AUTOSAR XML (schema 00050)
package /FCADT/ComponentTypes
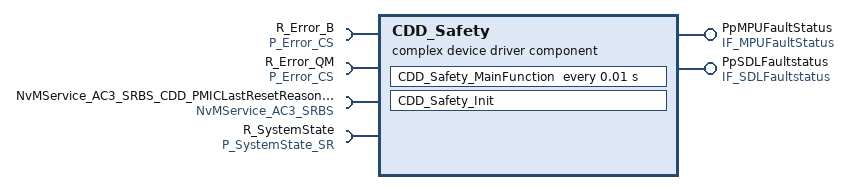
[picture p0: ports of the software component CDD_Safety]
  complex device driver sw component type CDD_Safety
    require port R_Error_B: client-com-spec=ReportErrorStatus1_0_B, required-interface=P_Error_CS
    require port R_Error_QM: client-com-spec=ReportErrorStatus1_0_QM, required-interface=P_Error_CS
    provide port PpMPUFaultStatus: nonqueued-sender-com-spec{data-element=Sts, init-value=[0, 0]}, provided-interface=IF_MPUFaultStatus
    provide port PpSDLFaultstatus: nonqueued-sender-com-spec{data-element=Sts, init-value=14 x 0}, provided-interface=IF_SDLFaultstatus
    require port NvMService_AC3_SRBS_CDD_PMICLastResetReason_BISTStatus: required-com-specs=[WriteBlock, SetRamBlockStatus, ReadBlock, InvalidateNvBlock, GetErrorStatus, EraseBlock], required-interface=NvMService_AC3_SRBS
    require port R_SystemState: nonqueued-receiver-com-spec=data-element=SystemState, required-interface=P_SystemState_SR
    behavior CDD_Safety_InternalBehavior
      ar-typed-per-instance-memorys:
        data CDD_PMICLastResetReason_BISTStatus_MirrorBlock: sw-calibration-access=READ-ONLY, type=Arr_2Byte
      timing event TMT_Safety_CDD_MainFunction: start-on-event=CDD_Safety_MainFunction, period=0.01
      per-instance-parameters:
        parameter data prototype CDD_PMICLastResetReason_BISTStatus_DefaultValue: sw-calibration-access=READ-WRITE, type=Arr_2Byte, init-value=[rule-based-values={rule=FILL_UNTIL_END, rule-arguments=0}]
      runnable CDD_Safety_Init
      runnable CDD_Safety_MainFunction
        data-receive-point-by-arguments:
          access REC_R_SystemState_SystemState: accessed-variable=R_SystemState.SystemState
        data-send-points:
          access SEND_PpMPUFaultStatus_Sts: accessed-variable=PpMPUFaultStatus.Sts
          access SEND_PpSDLFaultstatus_Sts: accessed-variable=PpSDLFaultstatus.Sts
        sync call SC_R_Error_ReportErrorStatus1_0_B: operation=R_Error_B.ReportErrorStatus1_0_B
        sync call SC_R_Error_QM_ReportErrorStatus1_0_QM: operation=R_Error_QM.ReportErrorStatus1_0_QM
        sync call SC_NvMService_AC3_SRBS_CDD_PMICLastResetReason_BISTStatus_WriteBlock: operation=NvMService_AC3_SRBS_CDD_PMICLastResetReason_BISTStatus.WriteBlock
      swc service dependency CDD_PMICLastResetReason_BISTStatus: category=SERVICE, assigned-datas=role-based-data-assignment={role=defaultValue, used-parameter-element=CDD_PMICLastResetReason_BISTStatus_DefaultValue}, assigned-ports=role-based-port-assignment={port-prototype=NvMService_AC3_SRBS_CDD_PMICLastResetReason_BISTStatus, role=NvMService_AC3_SRBS}
        service-needs:
          nv block needs CDD_PMICLastResetReason_BISTStatus: n-data-sets=1, ram-block-status-control=API, reliability=NO-PROTECTION, restore-at-start=true, store-at-shutdown=true, store-immediate=true
  swc implementation CDD_Safety_Implementation: behavior=CDD_Safety_InternalBehavior
